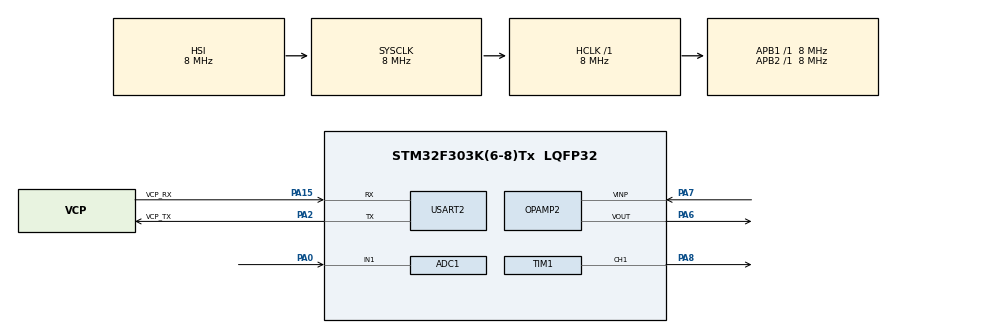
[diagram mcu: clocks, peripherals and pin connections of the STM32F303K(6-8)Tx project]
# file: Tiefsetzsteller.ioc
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ADC1.Channel-0\#ChannelRegularConversion=ADC_CHANNEL_1
ADC1.ClockPrescaler=ADC_CLOCK_ASYNC_DIV1
ADC1.ContinuousConvMode=ENABLE
ADC1.Mode=ADC_MODE_INDEPENDENT
ADC1.NbrOfConversionFlag=1
ADC1.Offset-0\#ChannelRegularConversion=0
ADC1.OffsetNumber-0\#ChannelRegularConversion=ADC_OFFSET_NONE
ADC1.Rank-0\#ChannelRegularConversion=1
ADC1.SamplingTime-0\#ChannelRegularConversion=ADC_SAMPLETIME_1CYCLE_5
ADC1.master=1
ADC2.Channel-1\#ChannelRegularConversion=ADC_CHANNEL_3
ADC2.ContinuousConvMode=ENABLE
ADC2.NbrOfConversionFlag=1
ADC2.Offset-1\#ChannelRegularConversion=0
ADC2.OffsetNumber-1\#ChannelRegularConversion=ADC_OFFSET_NONE
ADC2.Rank-1\#ChannelRegularConversion=1
ADC2.SamplingTime-1\#ChannelRegularConversion=ADC_SAMPLETIME_1CYCLE_5
Mcu.Family=STM32F3
Mcu.Name=STM32F303K(6-8)Tx
Mcu.Package=LQFP32
NVIC.PriorityGroup=NVIC_PRIORITYGROUP_4
OPAMP2.PgaGain=OPAMP_PGA_GAIN_2
PA0.Mode=IN1-Single-Ended
PA0.Signal=ADC1_IN1
PA13.GPIO_Label=SWDIO
PA13.Mode=Serial_Wire
PA13.Signal=SYS_JTMS-SWDIO
PA14.GPIO_Label=SWCLK
PA14.Mode=Serial_Wire
PA14.Signal=SYS_JTCK-SWCLK
PA15.GPIO_Label=VCP_RX
PA15.Mode=Asynchronous
PA15.Signal=USART2_RX
PA2.GPIO_Label=VCP_TX
PA2.Mode=Asynchronous
PA2.Signal=USART2_TX
PA6.Mode=PGA Not Connected
PA6.Signal=OPAMP2_VOUT
PA7.Mode=PGA Not Connected
PA7.Signal=OPAMP2_VINP
PA8.Signal=S_TIM1_CH1
PF0\ /\ OSC_IN.GPIO_Label=MCO
PF0\ /\ OSC_IN.Mode=HSE-External-Clock-Source
PF0\ /\ OSC_IN.Signal=RCC_OSC_IN
ProjectManager.HeapSize=0x200
ProjectManager.StackSize=0x400
ProjectManager.TargetToolchain=STM32CubeIDE
RCC.AHBFreq_Value=8000000
RCC.APB1Freq_Value=8000000
RCC.APB2Freq_Value=8000000
RCC.CortexFreq_Value=8000000
RCC.HSE_VALUE=8000000
RCC.HSI_VALUE=8000000
RCC.PLLMUL=RCC_PLL_MUL4
RCC.SYSCLKFreq_VALUE=8000000
SH.S_TIM1_CH1.0=TIM1_CH1,PWM Generation1 CH1
TIM1.Channel-PWM\ Generation1\ CH1=TIM_CHANNEL_1
TIM1.Period=57
USART2.VirtualMode-Asynchronous=VM_ASYNC
VP_ADC1_Vref_Input.Mode=IN-Vrefint
VP_ADC2_OPAMP_OUT2.Mode=IN3-OPAMP2-Single-Ended
VP_ADC2_Vref_Input.Mode=IN-Vrefint
board=NUCLEO-F303K8

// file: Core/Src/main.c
/* USER CODE BEGIN Header */
/**
  ******************************************************************************
  * @file           : main.c
  * @brief          : Main program body
  ******************************************************************************
  * @attention
  *
  * <h2><center>&copy; Copyright (c) 2020 STMicroelectronics.
  * All rights reserved.</center></h2>
  *
  * This software component is licensed by ST under BSD 3-Clause license,
  * the "License"; You may not use this file except in compliance with the
  * License. You may obtain a copy of the License at:
  *                        opensource.org/licenses/BSD-3-Clause
  *
  ******************************************************************************
  */
/* USER CODE END Header */

#include "main.h"

/* USER CODE BEGIN PTD */
extern initialise_monitor_handles(void);
/* USER CODE END PTD */

ADC_HandleTypeDef hadc1;
ADC_HandleTypeDef hadc2;

OPAMP_HandleTypeDef hopamp2;

TIM_HandleTypeDef htim1;

UART_HandleTypeDef huart2;

/* USER CODE BEGIN PV */
float ADC_value1;
float ADC_value2;
/* USER CODE END PV */

void SystemClock_Config(void);
static void MX_GPIO_Init(void);
static void MX_USART2_UART_Init(void);
static void MX_TIM1_Init(void);
static void MX_ADC1_Init(void);
static void MX_OPAMP2_Init(void);
static void MX_ADC2_Init(void);

int main(void)
{
  /* USER CODE BEGIN 1 */
  // initialise_monitor_handles();
  /* USER CODE END 1 */

  /* MCU Configuration--------------------------------------------------------*/

  /* Reset of all peripherals, Initializes the Flash interface and the Systick. */
  HAL_Init();

  /* USER CODE BEGIN Init */
  initialise_monitor_handles();
  /* USER CODE END Init */

  /* Configure the system clock */
  SystemClock_Config();

  /* Initialize all configured peripherals */
  MX_GPIO_Init();
  MX_USART2_UART_Init();
  MX_TIM1_Init();
  MX_ADC1_Init();
  MX_OPAMP2_Init();
  MX_ADC2_Init();
  /* USER CODE BEGIN 2 */
  HAL_ADC_Start(&hadc2);
  HAL_ADC_Start(&hadc1);

  HAL_TIM_PWM_Start(&htim1,TIM_CHANNEL_1);

  HAL_OPAMP_Start(&hopamp2);
  /* USER CODE END 2 */

  /* Infinite loop */
  /* USER CODE BEGIN WHILE */
  while (1)
  {
	  ADC_value2 = ( HAL_ADC_GetValue(&hadc2)/ (4095.0 * 2) )*3.3 *1000;
	  printf("Ladestrom I [mA] %f \n", ADC_value1);
	//  ADC_value1 = ( HAL_ADC_GetValue(&hadc2)/ (4095.0 * 2) )*3.3 *1000;
	  printf("Vref [V] %f \n", HAL_ADC_GetValue(&hadc2));
    /* USER CODE END WHILE */

  }
}

void SystemClock_Config(void)
{
  RCC_OscInitTypeDef RCC_OscInitStruct = {0};
  RCC_ClkInitTypeDef RCC_ClkInitStruct = {0};
  RCC_PeriphCLKInitTypeDef PeriphClkInit = {0};

  /** Initializes the CPU, AHB and APB busses clocks
  */
  RCC_OscInitStruct.OscillatorType = RCC_OSCILLATORTYPE_HSI;
  RCC_OscInitStruct.HSIState = RCC_HSI_ON;
  RCC_OscInitStruct.HSICalibrationValue = RCC_HSICALIBRATION_DEFAULT;
  RCC_OscInitStruct.PLL.PLLState = RCC_PLL_ON;
  RCC_OscInitStruct.PLL.PLLSource = RCC_PLLSOURCE_HSI;
  RCC_OscInitStruct.PLL.PLLMUL = RCC_PLL_MUL4;
  if (HAL_RCC_OscConfig(&RCC_OscInitStruct) != HAL_OK)
  {
    Error_Handler();
  }
  /** Initializes the CPU, AHB and APB busses clocks
  */
  RCC_ClkInitStruct.ClockType = RCC_CLOCKTYPE_HCLK|RCC_CLOCKTYPE_SYSCLK
                              |RCC_CLOCKTYPE_PCLK1|RCC_CLOCKTYPE_PCLK2;
  RCC_ClkInitStruct.SYSCLKSource = RCC_SYSCLKSOURCE_HSI;
  RCC_ClkInitStruct.AHBCLKDivider = RCC_SYSCLK_DIV1;
  RCC_ClkInitStruct.APB1CLKDivider = RCC_HCLK_DIV1;
  RCC_ClkInitStruct.APB2CLKDivider = RCC_HCLK_DIV1;

  if (HAL_RCC_ClockConfig(&RCC_ClkInitStruct, FLASH_LATENCY_0) != HAL_OK)
  {
    Error_Handler();
  }
  PeriphClkInit.PeriphClockSelection = RCC_PERIPHCLK_TIM1|RCC_PERIPHCLK_ADC12;
  PeriphClkInit.Adc12ClockSelection = RCC_ADC12PLLCLK_DIV1;
  PeriphClkInit.Tim1ClockSelection = RCC_TIM1CLK_HCLK;
  if (HAL_RCCEx_PeriphCLKConfig(&PeriphClkInit) != HAL_OK)
  {
    Error_Handler();
  }
}

static void MX_ADC1_Init(void)
{

  ADC_MultiModeTypeDef multimode = {0};
  ADC_ChannelConfTypeDef sConfig = {0};

  /** Common config
  */
  hadc1.Instance = ADC1;
  hadc1.Init.ClockPrescaler = ADC_CLOCK_ASYNC_DIV1;
  hadc1.Init.Resolution = ADC_RESOLUTION_12B;
  hadc1.Init.ScanConvMode = ADC_SCAN_DISABLE;
  hadc1.Init.ContinuousConvMode = ENABLE;
  hadc1.Init.DiscontinuousConvMode = DISABLE;
  hadc1.Init.ExternalTrigConvEdge = ADC_EXTERNALTRIGCONVEDGE_NONE;
  hadc1.Init.ExternalTrigConv = ADC_SOFTWARE_START;
  hadc1.Init.DataAlign = ADC_DATAALIGN_RIGHT;
  hadc1.Init.NbrOfConversion = 1;
  hadc1.Init.DMAContinuousRequests = DISABLE;
  hadc1.Init.EOCSelection = ADC_EOC_SINGLE_CONV;
  hadc1.Init.LowPowerAutoWait = DISABLE;
  hadc1.Init.Overrun = ADC_OVR_DATA_OVERWRITTEN;
  if (HAL_ADC_Init(&hadc1) != HAL_OK)
  {
    Error_Handler();
  }
  /** Configure the ADC multi-mode
  */
  multimode.Mode = ADC_MODE_INDEPENDENT;
  if (HAL_ADCEx_MultiModeConfigChannel(&hadc1, &multimode) != HAL_OK)
  {
    Error_Handler();
  }
  /** Configure Regular Channel
  */
  sConfig.Channel = ADC_CHANNEL_18;
  sConfig.Rank = ADC_REGULAR_RANK_1;
  sConfig.SingleDiff = ADC_SINGLE_ENDED;
  sConfig.SamplingTime = ADC_SAMPLETIME_1CYCLE_5;
  sConfig.OffsetNumber = ADC_OFFSET_NONE;
  sConfig.Offset = 0;
  if (HAL_ADC_ConfigChannel(&hadc1, &sConfig) != HAL_OK)
  {
    Error_Handler();
  }

}

static void MX_ADC2_Init(void)
{

  ADC_ChannelConfTypeDef sConfig = {0};

  /** Common config
  */
  hadc2.Instance = ADC2;
  hadc2.Init.ClockPrescaler = ADC_CLOCK_ASYNC_DIV1;
  hadc2.Init.Resolution = ADC_RESOLUTION_12B;
  hadc2.Init.ScanConvMode = ADC_SCAN_DISABLE;
  hadc2.Init.ContinuousConvMode = ENABLE;
  hadc2.Init.DiscontinuousConvMode = DISABLE;
  hadc2.Init.ExternalTrigConvEdge = ADC_EXTERNALTRIGCONVEDGE_NONE;
  hadc2.Init.ExternalTrigConv = ADC_SOFTWARE_START;
  hadc2.Init.DataAlign = ADC_DATAALIGN_RIGHT;
  hadc2.Init.NbrOfConversion = 1;
  hadc2.Init.DMAContinuousRequests = DISABLE;
  hadc2.Init.EOCSelection = ADC_EOC_SINGLE_CONV;
  hadc2.Init.LowPowerAutoWait = DISABLE;
  hadc2.Init.Overrun = ADC_OVR_DATA_OVERWRITTEN;
  if (HAL_ADC_Init(&hadc2) != HAL_OK)
  {
    Error_Handler();
  }
  /** Configure Regular Channel
  */
  sConfig.Channel = ADC_CHANNEL_18;
  sConfig.Rank = ADC_REGULAR_RANK_1;
  sConfig.SingleDiff = ADC_SINGLE_ENDED;
  sConfig.SamplingTime = ADC_SAMPLETIME_1CYCLE_5;
  sConfig.OffsetNumber = ADC_OFFSET_NONE;
  sConfig.Offset = 0;
  if (HAL_ADC_ConfigChannel(&hadc2, &sConfig) != HAL_OK)
  {
    Error_Handler();
  }

}

static void MX_OPAMP2_Init(void)
{

  hopamp2.Instance = OPAMP2;
  hopamp2.Init.Mode = OPAMP_PGA_MODE;
  hopamp2.Init.NonInvertingInput = OPAMP_NONINVERTINGINPUT_IO0;
  hopamp2.Init.TimerControlledMuxmode = OPAMP_TIMERCONTROLLEDMUXMODE_DISABLE;
  hopamp2.Init.PgaConnect = OPAMP_PGA_CONNECT_INVERTINGINPUT_NO;
  hopamp2.Init.PgaGain = OPAMP_PGA_GAIN_2;
  hopamp2.Init.UserTrimming = OPAMP_TRIMMING_FACTORY;
  if (HAL_OPAMP_Init(&hopamp2) != HAL_OK)
  {
    Error_Handler();
  }

}

static void MX_TIM1_Init(void)
{

  TIM_MasterConfigTypeDef sMasterConfig = {0};
  TIM_OC_InitTypeDef sConfigOC = {0};
  TIM_BreakDeadTimeConfigTypeDef sBreakDeadTimeConfig = {0};

  htim1.Instance = TIM1;
  htim1.Init.Prescaler = 0;
  htim1.Init.CounterMode = TIM_COUNTERMODE_UP;
  htim1.Init.Period = 57;
  htim1.Init.ClockDivision = TIM_CLOCKDIVISION_DIV1;
  htim1.Init.RepetitionCounter = 0;
  htim1.Init.AutoReloadPreload = TIM_AUTORELOAD_PRELOAD_DISABLE;
  if (HAL_TIM_PWM_Init(&htim1) != HAL_OK)
  {
    Error_Handler();
  }
  sMasterConfig.MasterOutputTrigger = TIM_TRGO_RESET;
  sMasterConfig.MasterOutputTrigger2 = TIM_TRGO2_RESET;
  sMasterConfig.MasterSlaveMode = TIM_MASTERSLAVEMODE_DISABLE;
  if (HAL_TIMEx_MasterConfigSynchronization(&htim1, &sMasterConfig) != HAL_OK)
  {
    Error_Handler();
  }
  sConfigOC.OCMode = TIM_OCMODE_PWM1;
  sConfigOC.Pulse = 0;
  sConfigOC.OCPolarity = TIM_OCPOLARITY_HIGH;
  sConfigOC.OCNPolarity = TIM_OCNPOLARITY_HIGH;
  sConfigOC.OCFastMode = TIM_OCFAST_DISABLE;
  sConfigOC.OCIdleState = TIM_OCIDLESTATE_RESET;
  sConfigOC.OCNIdleState = TIM_OCNIDLESTATE_RESET;
  if (HAL_TIM_PWM_ConfigChannel(&htim1, &sConfigOC, TIM_CHANNEL_1) != HAL_OK)
  {
    Error_Handler();
  }
  sBreakDeadTimeConfig.OffStateRunMode = TIM_OSSR_DISABLE;
  sBreakDeadTimeConfig.OffStateIDLEMode = TIM_OSSI_DISABLE;
  sBreakDeadTimeConfig.LockLevel = TIM_LOCKLEVEL_OFF;
  sBreakDeadTimeConfig.DeadTime = 0;
  sBreakDeadTimeConfig.BreakState = TIM_BREAK_DISABLE;
  sBreakDeadTimeConfig.BreakPolarity = TIM_BREAKPOLARITY_HIGH;
  sBreakDeadTimeConfig.BreakFilter = 0;
  sBreakDeadTimeConfig.Break2State = TIM_BREAK2_DISABLE;
  sBreakDeadTimeConfig.Break2Polarity = TIM_BREAK2POLARITY_HIGH;
  sBreakDeadTimeConfig.Break2Filter = 0;
  sBreakDeadTimeConfig.AutomaticOutput = TIM_AUTOMATICOUTPUT_DISABLE;
  if (HAL_TIMEx_ConfigBreakDeadTime(&htim1, &sBreakDeadTimeConfig) != HAL_OK)
  {
    Error_Handler();
  }
  HAL_TIM_MspPostInit(&htim1);

}

static void MX_USART2_UART_Init(void)
{

  huart2.Instance = USART2;
  huart2.Init.BaudRate = 38400;
  huart2.Init.WordLength = UART_WORDLENGTH_8B;
  huart2.Init.StopBits = UART_STOPBITS_1;
  huart2.Init.Parity = UART_PARITY_NONE;
  huart2.Init.Mode = UART_MODE_TX_RX;
  huart2.Init.HwFlowCtl = UART_HWCONTROL_NONE;
  huart2.Init.OverSampling = UART_OVERSAMPLING_16;
  huart2.Init.OneBitSampling = UART_ONE_BIT_SAMPLE_DISABLE;
  huart2.AdvancedInit.AdvFeatureInit = UART_ADVFEATURE_NO_INIT;
  if (HAL_UART_Init(&huart2) != HAL_OK)
  {
    Error_Handler();
  }

}

static void MX_GPIO_Init(void)
{

  /* GPIO Ports Clock Enable */
  __HAL_RCC_GPIOF_CLK_ENABLE();
  __HAL_RCC_GPIOA_CLK_ENABLE();

}

void Error_Handler(void)
{
}

/************************ (C) COPYRIGHT STMicroelectronics *****END OF FILE****/
